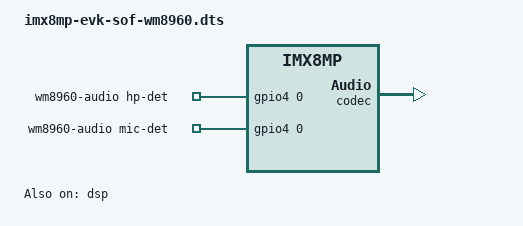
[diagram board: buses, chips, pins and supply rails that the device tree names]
// SPDX-License-Identifier: GPL-2.0+
// Copyright NXP 2020

#include "imx8mp-evk.dts"

/ {
	sound-wm8960 {
		status = "disabled";
	};

	sound-micfil {
		status = "disabled";
	};

	sof-sound-wm8960 {
		compatible = "simple-audio-card";
		label = "wm8960-audio";
		simple-audio-card,bitclock-master = <&sndcodec>;
		simple-audio-card,frame-master = <&sndcodec>;
		simple-audio-card,hp-det-gpio = <&gpio4 0 0>;
		simple-audio-card,mic-det-gpio = <&gpio4 0 0>;
		simple-audio-card,widgets =
			"Headphone", "Headphone Jack",
			"Speaker", "Ext Spk",
			"Microphone", "Mic Jack";
		simple-audio-card,audio-routing =
			"Headphone Jack", "HP_L",
			"Headphone Jack", "HP_R",
			"Ext Spk", "SPK_LP",
			"Ext Spk", "SPK_LN",
			"Ext Spk", "SPK_RP",
			"Ext Spk", "SPK_RN",
			"LINPUT2", "Mic Jack",
			"LINPUT3", "Mic Jack",
			"RINPUT1", "Mic Jack",
			"RINPUT2", "Mic Jack",
			"Playback", "SAI3.OUT",
			"SAI3.IN", "Capture";
		simple-audio-card,dai-link {
			format = "i2s";
			cpu {
				sound-dai = <&dsp 0>;
			};
			sndcodec: codec {
				sound-dai = <&codec>;
			};
		};
	};
};

&dsp {
	#sound-dai-cells = <1>;
	compatible = "fsl,imx8mp-dsp";

	pinctrl-names = "default";
	pinctrl-0 = <&pinctrl_sai3>;

	power-domains = <&audiomix_pd>;
	clocks = <&audiomix_clk IMX8MP_CLK_AUDIOMIX_OCRAMA_IPG>,
			<&audiomix_clk IMX8MP_CLK_AUDIOMIX_DSP_ROOT>,
			<&audiomix_clk IMX8MP_CLK_AUDIOMIX_DSPDBG_ROOT>,
			<&audiomix_clk IMX8MP_CLK_AUDIOMIX_MU2_ROOT>,
			<&audiomix_clk IMX8MP_CLK_AUDIOMIX_SDMA3_ROOT>,
			<&audiomix_clk IMX8MP_CLK_AUDIOMIX_SAI3_IPG>,
			<&clk IMX8MP_CLK_DUMMY>,
			<&audiomix_clk IMX8MP_CLK_AUDIOMIX_SAI3_MCLK1>,
			<&clk IMX8MP_CLK_DUMMY>,
			<&clk IMX8MP_CLK_DUMMY>;
	clock-names = "ocram", "core", "debug", "mu2", "sdma3",
		"sai3_bus", "sai3_mclk0", "sai3_mclk1", "sai3_mclk2", "sai3_mclk3";

	assigned-clocks = <&clk IMX8MP_CLK_SAI3>;
	assigned-clock-parents = <&clk IMX8MP_AUDIO_PLL1_OUT>;
	assigned-clock-rates = <12288000>;


	reg = <0x0 0x3B6E8000 0x0 0x88000>;
	tplg-name = "sof-imx8mp-wm8960.tplg";

	machine-drv-name = "asoc-simple-card";
	status = "okay";
};

&codec {
	#sound-dai-cells = <0>;
	status = "okay";
};

&sai3 {
	status = "disabled";
};

&sdma3 {
	status = "disabled";
};
